# PN74xxAU register map
File version: 2
CPU: CM0 r0p0, little endian, no MPU, no FPU, 2 interrupt priority bits
Registers are 32-bit, read-write, reset 0x0 unless marked. A register's access mark holds for its fields unless they carry their own. Offsets are from the block's base; [hi:lo] are bit positions; {n}, {i} and the like mark numbered series.

## CT — Contact Interface
Base 0x40014000
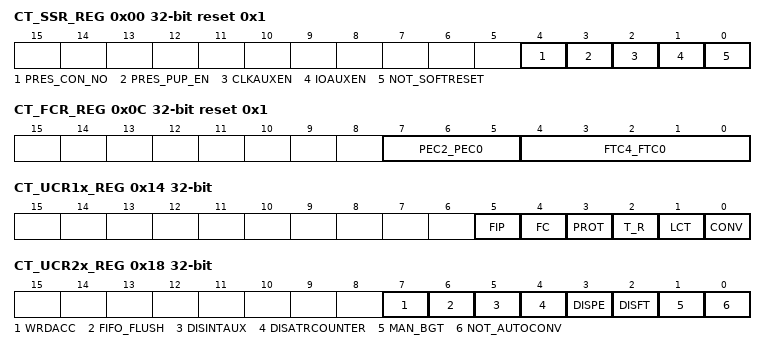
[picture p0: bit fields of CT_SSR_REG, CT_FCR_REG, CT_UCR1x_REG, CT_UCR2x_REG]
0x00 CT_SSR_REG reset 0x1 — Slot Select Register
  [4] PRES_CON_NO — PRESN Connector Normally Open
  [3] PRES_PUP_EN — PRESN internal Pull Up Enable
  [2] CLKAUXEN — CLKAUX clock enable signal
  [1] IOAUXEN — Select the second (auxiliary) slot
  [0] NOT_SOFTRESET — Software reset
0x04 CT_PDRx_LSB_REG reset 0x74 — Programmable Divider Register Least Significant Byte slot x (PDR LSB register of main slot accessed when IOAUXen = 0, else PDR LSB register of auxiliary slot accessed)
  [7:0] PD7_PD0 — Programmable Divider Least Significant Byte
0x08 CT_PDRx_MSB_REG reset 0x1 — Programmable Divider Register Most Significant Byte slot x (PDR MSB register of main slot accessed when IOAUXen = 0, else PDR MSB register of auxiliary slot accessed)
  [7:0] PD15_PD8 — Programmable Divider Most Significant Byte
0x0C CT_FCR_REG reset 0x1 — FIFO Control Register
  [7:5] PEC2_PEC0 — Parity Error counter
  [4:0] FTC4_FTC0 — FIFO Threshold Configuration
0x10 CT_GTRx_REG — Guard Time Register slot x (GTR register of main slot accessed when IOAUXen = 0, else GTR register of auxiliary slot accessed)
  [7:0] GT7_GT0 — Guard time
0x14 CT_UCR1x_REG — UART Configuration Register 1 slot x (UCR1 register of main slot accessed when IOAUXen = 0, else UCR1 register of auxiliary slot accessed)
  [5] FIP — Force Inverse Parity
  [4] FC
  [3] PROT — PROTocol
  [2] T_R — Transmit_Receive
  [1] LCT — Last Character to Transmit
  [0] CONV — CONVention
0x18 CT_UCR2x_REG — UART Configuration Register 2 slot x (UCR2 register of main slot accessed when IOAUXen = 0, else UCR2 register of auxiliary slot accessed)
  [7] WRDACC — FIFO WoRD ACCess
  [6] FIFO_FLUSH
  [5] DISINTAUX — DISable INTAUX
  [4] DISATRCOUNTER — DISable ATR counter
  [3] DISPE — DISable Parity Error interrupt bit
  [2] DISFT — DISable Fifo Threshold interrupt bit
  [1] MAN_BGT — MANual BGT
  [0] NOT_AUTOCONV — AUTOmatically detected CONVention
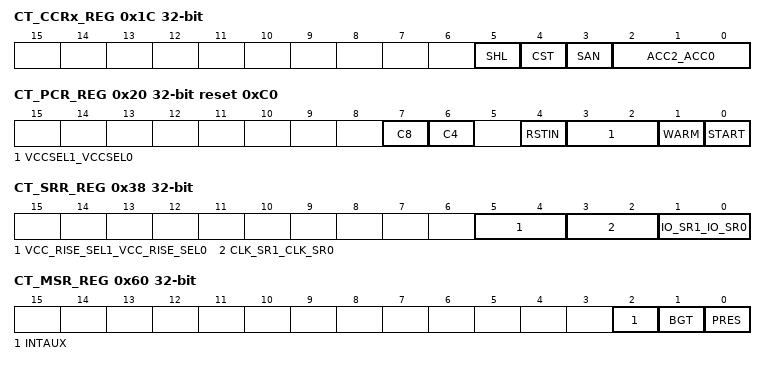
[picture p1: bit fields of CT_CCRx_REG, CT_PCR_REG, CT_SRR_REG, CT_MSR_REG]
0x1C CT_CCRx_REG — Clock Configuration Register slot x (CCR register of main slot accessed when IOAUXen = 0, else CCR register of auxiliary slot accessed)
  [5] SHL — Stop HIGH or LOW
  [4] CST — Clock Stop (RFU for auxiliary slot)
  [3] SAN — Synchronous Asynchronous Card
  [2:0] ACC2_ACC0 — Asynchronous Card Clock
0x20 CT_PCR_REG reset 0xC0 — Power Control Register
  [7] C8 — Contact 8
  [6] C4 — Contact 4
  [4] RSTIN — Reset bit
  [3:2] VCCSEL1_VCCSEL0 — Vcc selection
  [1] WARM
  [0] START
0x24 CT_ECR_REG reset 0xAA — Early answer CounteR
  [7:0] EC7_EC0
0x28 CT_MCLR_LSB_REG reset 0x74 — Mute card CounteR RST Low register Least Significant Byte
  [7:0] MCL7_MCL0 — Mute card CounteR RST Low Least Significant Byte
0x2C CT_MCLR_MSB_REG reset 0xA4 — Mute card CounteR RST Low register Most Significant Byte
  [7:0] MCL15_MCL7 — Mute card CounteR RST Low Most Significant Byte
0x30 CT_MCHR_LSB_REG reset 0x74 — Mute card CounteR RST HIGH register Least Significant Byte
  [7:0] MCH7_MCH0 — Mute card CounteR RST HIGH Least Significant Byte
0x34 CT_MCHR_MSB_REG reset 0xA4 — Mute card CounteR RST HIGH register Most Significant Byte
  [7:0] MCH15_MCH7 — Mute card CounteR RST HIGH Most Significant Byte
0x38 CT_SRR_REG — Slew Rate configuration Register
  [5:4] VCC_RISE_SEL1_VCC_RISE_SEL0 — Vcc rise time selection
  [3:2] CLK_SR1_CLK_SR0 — CLK slew rate
  [1:0] IO_SR1_IO_SR0 — IO slew rate
{0x38+4i} CT_UTR_URR_REG_adr{i} (i=1..4) — UART Transmit & Receive Register (FIFO access registers, URR used when reading, UTR used when writing, 4 contiguous addresses to support LDM/STM ARM instructions)
  [31:0] UTRURR31_UTRURR0 — Uart Transmit & Receive Register
{0x48+4i} CT_TOR{i}_REG wo (i=1..3) — Time-Out Register {i}
  [7:0] TOL{8i-1}_TOL{8i-8} — Time-Out Latched
0x58 CT_TOC_REG — Time-Out Configuration
  [7:0] TOC7_TOC0
0x5C CT_FSR_REG ro — FIFO Status Register
  [5:0] FFL5_FFL0 — FIFO Fulfilment Level
0x60 CT_MSR_REG ro — Mixed Status Register
  [2] INTAUX — Auxiliary interrupt
  [1] BGT — Block Guard Time
  [0] PRES — PRESence
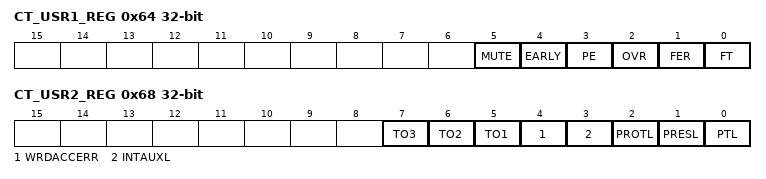
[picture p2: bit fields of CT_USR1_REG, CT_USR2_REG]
0x64 CT_USR1_REG ro — UART Status Register 1
  [5] MUTE — Card mute
  [4] EARLY — Early answer
  [3] PE — Parity Error
  [2] OVR — OverRun
  [1] FER — Framing Error
  [0] FT — Fifo Threshold
0x68 CT_USR2_REG ro — UART Status Register 2
  [7] TO3 — Time Out counter3
  [6] TO2 — Time Out counter2
  [5] TO1 — Time Out counter1
  [4] WRDACCERR — WoRD ACCess ERRor
  [3] INTAUXL — AUXiliary INTerrupt Latched
  [2] PROTL — PROTection Latched
  [1] PRESL — PRESence Latched
  [0] PTL — Protection Temperature Latched
